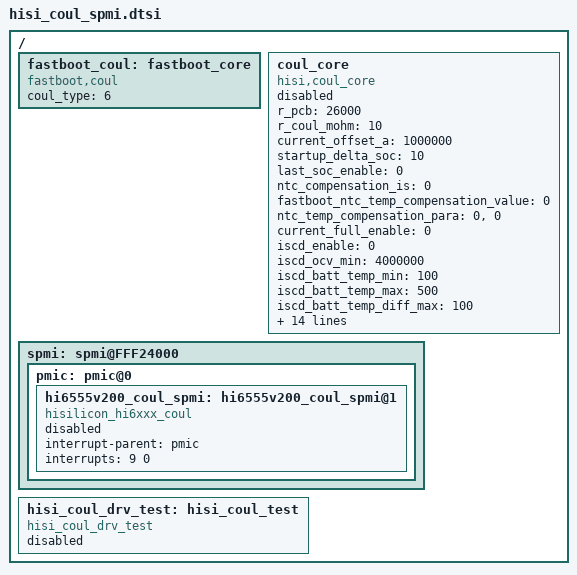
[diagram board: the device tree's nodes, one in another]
 / {
    fastboot_coul:fastboot_core {
        compatible = "fastboot,coul";
        coul_type = <6>; /*hi6555v200*/
        status = "ok";
    };
    coul_core:coul_core{
        compatible = "hisi,coul_core";
	    r_pcb = <26000>;	
	    r_coul_mohm = <10>;
	    current_offset_a = <1000000>;
	    startup_delta_soc = <10>;
	    last_soc_enable = <0>;
            ntc_compensation_is = <0>;
            fastboot_ntc_temp_compensation_value = <0>;
            ntc_temp_compensation_para =
                "0", "0";
		current_full_enable = <0>;
		iscd_enable = <0>;
		iscd_ocv_min = <4000000>;
		iscd_batt_temp_min = <100>;
		iscd_batt_temp_max = <500>;
		iscd_batt_temp_diff_max = <100>;
		iscd_sample_time_interval = <600>;
		iscd_sample_time_delay = <10>;
		iscd_calc_time_interval_min = <3600>;
		iscd_calc_time_interval_max = <21600>;
		iscd_level_warning_threhold = <10000>;
		iscd_level_error_threhold = <30000>;
		iscd_level_critical_threhold = <100000>;
		iscd_level_info = <
			0		10000	920001048	0	0	0
			10000	15000	920001049	0	0	0
			15000	20000	920001050	0	0	0
			20000	25000	920001051	0	0	0
			25000	30000	920001052	0	0	0
			30000	50000	920001053	0	0	0
			50000	100000	920001054	0	0	0
			100000	200000	920001055	0	0	0
			200000	9999999	920001056	0	0	0
		>;
        multi_ocv_open = <1>;
        fcc_update_limit = <1>;
        low_temp_opt_enable = <0>;
        normal_cutoff_vol_mv = <3150>;
        sleep_cutoff_vol_mv = <3350>;
        status = "disabled";
   };
   spmi: spmi@FFF24000 {
	 pmic: pmic@0 {
                 hi6555v200_coul_spmi: hi6555v200_coul_spmi@1 {
                         compatible = "hisilicon_hi6xxx_coul";
                         interrupt-parent = <&pmic>;
                         interrupts = <9 0>;
                         interrupt-names = "coulirq";                                            
                         status = "disabled";
                 };
	};
    };
   hisi_coul_drv_test:hisi_coul_test {
   	    compatible = "hisi_coul_drv_test";
	    status = "disabled";
   };
};
